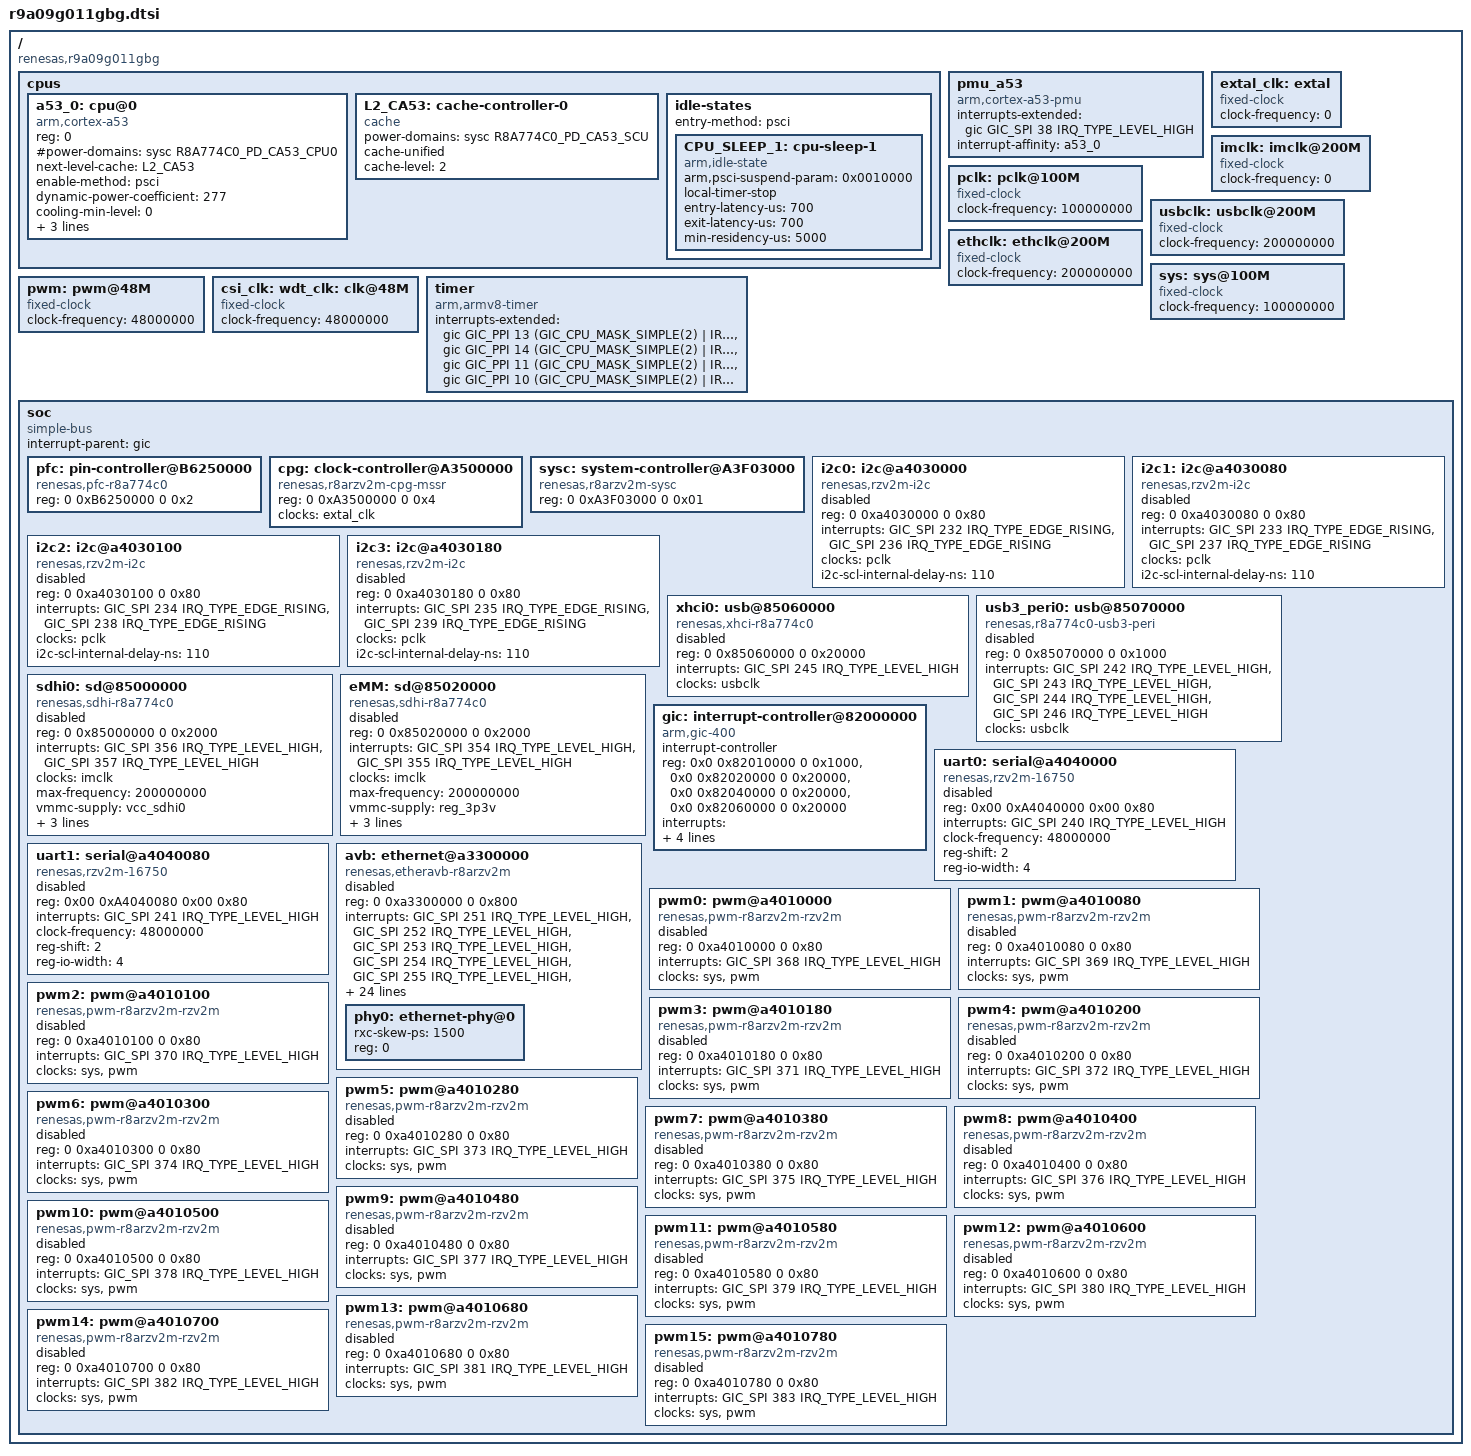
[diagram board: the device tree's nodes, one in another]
// SPDX-License-Identifier: GPL-2.0
/*
 * Device Tree Source for the RZ/V2M (R9A09G011GBG) SoC
 *
 * Copyright (C) 2019 Renesas Electronics Corp.
 */

#include <dt-bindings/clock/r9a09g011gbg-cpg-mssr.h>
#include <dt-bindings/interrupt-controller/arm-gic.h>
#include <dt-bindings/power/r9a09g011gbg-sysc.h>

/ {
    compatible = "renesas,r9a09g011gbg";
    #address-cells = <2>;
    #size-cells = <2>;


    cpus {
        #address-cells = <1>;
        #size-cells = <0>;

        a53_0: cpu@0 {
            compatible = "arm,cortex-a53", "arm,armv8";
            reg = <0>;
            device_type = "cpu";
            #power-domains = <&sysc R8A774C0_PD_CA53_CPU0>;
            next-level-cache = <&L2_CA53>;
            enable-method = "psci";
            #cooling-cells = <2>;
            dynamic-power-coefficient = <277>;
            cooling-min-level = <0>;
            cooling-max-level = <2>;
            cpu-idle-states = <&CPU_SLEEP_1>;
            clocks = <&cpg CPG_CORE R8A774C0_CLK_Z2>;
        };

        L2_CA53: cache-controller-0 {
            compatible = "cache";
            power-domains = <&sysc R8A774C0_PD_CA53_SCU>;
            cache-unified;
            cache-level = <2>;
        };

        idle-states {
            entry-method = "psci";

            CPU_SLEEP_1: cpu-sleep-1 {
                compatible = "arm,idle-state";
                arm,psci-suspend-param = <0x0010000>;
                local-timer-stop;
                entry-latency-us = <700>;
                exit-latency-us = <700>;
                min-residency-us = <5000>;
                status = "okay";
            };
        };
    };

    pmu_a53 { /* Support only for core0 not core1 */
        compatible = "arm,cortex-a53-pmu";
        interrupts-extended = <&gic GIC_SPI 38 IRQ_TYPE_LEVEL_HIGH>;
        interrupt-affinity = <&a53_0>;
    };

    /* used cpg(clock pulse generator) */
    extal_clk: extal {
        compatible = "fixed-clock";
        #clock-cells = <0>;
        /* This value must be overridden by the board */
        clock-frequency = <0>;
    };
    imclk: imclk@200M {
        #clock-cells = <0>;
        compatible = "fixed-clock";
        clock-frequency = <0>;
    };
    pclk: pclk@100M {
        #clock-cells = <0>;
        compatible = "fixed-clock";
        clock-frequency = <100000000>;
    };

    usbclk: usbclk@200M {
        #clock-cells = <0>;
        compatible = "fixed-clock";
        clock-frequency = <200000000>;
    };
    ethclk: ethclk@200M {
        #clock-cells = <0>;
        compatible = "fixed-clock";
        clock-frequency = <200000000>;
    };
    sys: sys@100M {
        #clock-cells = <0>;
        compatible = "fixed-clock";
        clock-frequency = <100000000>;
    };
    pwm: pwm@48M {
        #clock-cells = <0>;
        compatible = "fixed-clock";
        clock-frequency = <48000000>;
    };
    csi_clk: wdt_clk: pclk48: clk@48M {
        #clock-cells = <0>;
        compatible = "fixed-clock";
        clock-frequency = <48000000>;
    };

    timer {
        compatible = "arm,armv8-timer";
        interrupts-extended = <&gic GIC_PPI 13 (GIC_CPU_MASK_SIMPLE(2) | IRQ_TYPE_LEVEL_LOW)>,
                      <&gic GIC_PPI 14 (GIC_CPU_MASK_SIMPLE(2) | IRQ_TYPE_LEVEL_LOW)>,
                      <&gic GIC_PPI 11 (GIC_CPU_MASK_SIMPLE(2) | IRQ_TYPE_LEVEL_LOW)>,
                      <&gic GIC_PPI 10 (GIC_CPU_MASK_SIMPLE(2) | IRQ_TYPE_LEVEL_LOW)>;
    };

    soc: soc {
        compatible = "simple-bus";
        interrupt-parent = <&gic>;
        #address-cells = <2>;
        #size-cells = <2>;
        ranges;

        pfc: pin-controller@B6250000 {
            compatible = "renesas,pfc-r8a774c0";
            reg = <0 0xB6250000 0 0x2>;
        };

        cpg: clock-controller@A3500000 {
            compatible = "renesas,r8arzv2m-cpg-mssr";
            reg = <0 0xA3500000 0 0x4>;
            clocks = <&extal_clk>;
            clock-names = "extal";
            #clock-cells = <2>;
            #power-domain-cells = <0>;
            #reset-cells = <1>;
        };

        sysc: system-controller@A3F03000 {
            compatible = "renesas,r8arzv2m-sysc";
            reg = <0 0xA3F03000 0 0x01>;
            #power-domain-cells = <1>;
        };

        i2c0: i2c@a4030000 {
            #address-cells = <1>;
            #size-cells = <0>;
            compatible = "renesas,rzv2m-i2c";
            reg = <0 0xa4030000 0 0x80>;
            interrupts = <GIC_SPI 232 IRQ_TYPE_EDGE_RISING>,<GIC_SPI 236 IRQ_TYPE_EDGE_RISING>;
            clocks = <&pclk>;
            i2c-scl-internal-delay-ns = <110>;
            status = "disabled";
        };

        i2c1: i2c@a4030080 {
            #address-cells = <1>;
            #size-cells = <0>;
            compatible = "renesas,rzv2m-i2c";
            reg = <0 0xa4030080 0 0x80>;
            interrupts = <GIC_SPI 233 IRQ_TYPE_EDGE_RISING>,<GIC_SPI 237 IRQ_TYPE_EDGE_RISING>;
            clocks = <&pclk>;
            i2c-scl-internal-delay-ns = <110>;
            status = "disabled";
        };

        i2c2: i2c@a4030100 {
            #address-cells = <1>;
            #size-cells = <0>;
            compatible = "renesas,rzv2m-i2c";
            reg = <0 0xa4030100 0 0x80>;
            interrupts = <GIC_SPI 234 IRQ_TYPE_EDGE_RISING>,<GIC_SPI 238 IRQ_TYPE_EDGE_RISING>;
            clocks = <&pclk>;
            i2c-scl-internal-delay-ns = <110>;
            status = "disabled";
        };

        i2c3: i2c@a4030180 {
            #address-cells = <1>;
            #size-cells = <0>;
            compatible = "renesas,rzv2m-i2c";
            reg = <0 0xa4030180 0 0x80>;
            interrupts = <GIC_SPI 235 IRQ_TYPE_EDGE_RISING>,<GIC_SPI 239 IRQ_TYPE_EDGE_RISING>;
            clocks = <&pclk>;
            i2c-scl-internal-delay-ns = <110>;
            status = "disabled";
        };

        xhci0: usb@85060000 {
            compatible = "renesas,xhci-r8a774c0",
                     "renesas,rzv2m-xhci";
            reg = <0 0x85060000 0 0x20000>;
            interrupts = <GIC_SPI 245 IRQ_TYPE_LEVEL_HIGH>;
            clocks =  <&usbclk>;
            status = "disabled";
        };

        usb3_peri0: usb@85070000 {
            compatible = "renesas,r8a774c0-usb3-peri",
                     "renesas,rcar-gen3-usb3-peri";
            reg = <0 0x85070000 0 0x1000>;
            interrupts = <GIC_SPI 242 IRQ_TYPE_LEVEL_HIGH>,
                     <GIC_SPI 243 IRQ_TYPE_LEVEL_HIGH>,
                     <GIC_SPI 244 IRQ_TYPE_LEVEL_HIGH>,
                     <GIC_SPI 246 IRQ_TYPE_LEVEL_HIGH>;
            clocks =  <&usbclk>;
            status = "disabled";
        };

        sdhi0: sd@85000000 {    /* used sh card boot */
            compatible = "renesas,sdhi-r8a774c0",
                     "renesas,rcar-gen3-sdhi";
            reg = <0 0x85000000 0 0x2000>;
            interrupts = <GIC_SPI 356 IRQ_TYPE_LEVEL_HIGH>, <GIC_SPI 357 IRQ_TYPE_LEVEL_HIGH>;
            clocks = <&imclk>;
            max-frequency = <200000000>;
            vmmc-supply = <&vcc_sdhi0>;
            bus-width = <4>;
            sd-uhs-sdr50;
            sd-uhs-sdr104;
            status = "disable";
        };

        eMM: sd@85020000 {
            compatible = "renesas,sdhi-r8a774c0",
                    "renesas,rcar-gen3-sdhi";
            reg = <0 0x85020000 0 0x2000>;
            interrupts = <GIC_SPI 354 IRQ_TYPE_LEVEL_HIGH>, <GIC_SPI 355 IRQ_TYPE_LEVEL_HIGH>;
            clocks = <&imclk>;
            max-frequency = <200000000>;
            vmmc-supply = <&reg_3p3v>;
            vqmmc-supply = <&reg_1p8v>;
            bus-width = <8>;
            non-removable;
            status = "disable";
        };

        gic: interrupt-controller@82000000 {
            compatible = "arm,gic-400";
            #interrupt-cells = <3>;
            #address-cells = <0>;
            interrupt-controller;
            reg = <0x0 0x82010000 0 0x1000>,
                  <0x0 0x82020000 0 0x20000>,
                  <0x0 0x82040000 0 0x20000>,
                  <0x0 0x82060000 0 0x20000>;
            interrupts = <GIC_PPI 9
                    (GIC_CPU_MASK_SIMPLE(2) | IRQ_TYPE_LEVEL_HIGH)>;
            clocks = <&cpg CPG_MOD 408>;
            clock-names = "clk";
            power-domains = <&sysc R8A774C0_PD_ALWAYS_ON>;
            resets = <&cpg 408>;
        };

        uart0: serial@a4040000 {
            compatible = "renesas,rzv2m-16750", "ns16750";
            reg = <0x00 0xA4040000 0x00 0x80>;
            interrupts = <GIC_SPI 240 IRQ_TYPE_LEVEL_HIGH>;
            clock-frequency = <48000000>;
            reg-shift = <2>;
            reg-io-width = <4>;
            status = "disabled";
        };

        uart1: serial@a4040080 {
            compatible = "renesas,rzv2m-16750", "ns16750";
            reg = <0x00 0xA4040080 0x00 0x80>;
            interrupts = <GIC_SPI 241 IRQ_TYPE_LEVEL_HIGH>;
            clock-frequency = <48000000>;
            reg-shift = <2>;
            reg-io-width = <4>;
            status = "disabled";
        };

        avb: ethernet@a3300000 {
            compatible = "renesas,etheravb-r8arzv2m",
                     "renesas,etheravb-rcar-gen3";
            reg = <0 0xa3300000 0 0x800>;
            interrupts = <GIC_SPI 251 IRQ_TYPE_LEVEL_HIGH>,
                     <GIC_SPI 252 IRQ_TYPE_LEVEL_HIGH>,
                     <GIC_SPI 253 IRQ_TYPE_LEVEL_HIGH>,
                     <GIC_SPI 254 IRQ_TYPE_LEVEL_HIGH>,
                     <GIC_SPI 255 IRQ_TYPE_LEVEL_HIGH>,
                     <GIC_SPI 256 IRQ_TYPE_LEVEL_HIGH>,
                     <GIC_SPI 257 IRQ_TYPE_LEVEL_HIGH>,
                     <GIC_SPI 258 IRQ_TYPE_LEVEL_HIGH>,
                     <GIC_SPI 259 IRQ_TYPE_LEVEL_HIGH>,
                     <GIC_SPI 260 IRQ_TYPE_LEVEL_HIGH>,
                     <GIC_SPI 261 IRQ_TYPE_LEVEL_HIGH>,
                     <GIC_SPI 262 IRQ_TYPE_LEVEL_HIGH>,
                     <GIC_SPI 263 IRQ_TYPE_LEVEL_HIGH>,
                     <GIC_SPI 264 IRQ_TYPE_LEVEL_HIGH>,
                     <GIC_SPI 265 IRQ_TYPE_LEVEL_HIGH>,
                     <GIC_SPI 266 IRQ_TYPE_LEVEL_HIGH>,
                     <GIC_SPI 267 IRQ_TYPE_LEVEL_HIGH>,
                     <GIC_SPI 268 IRQ_TYPE_LEVEL_HIGH>,
                     <GIC_SPI 269 IRQ_TYPE_LEVEL_HIGH>,
                     <GIC_SPI 270 IRQ_TYPE_LEVEL_HIGH>,
                     <GIC_SPI 271 IRQ_TYPE_LEVEL_HIGH>,
                     <GIC_SPI 272 IRQ_TYPE_LEVEL_HIGH>,
                     <GIC_SPI 273 IRQ_TYPE_LEVEL_HIGH
                     GIC_SPI 275 IRQ_TYPE_LEVEL_HIGH
                     GIC_SPI 277 IRQ_TYPE_LEVEL_HIGH>,
                     <GIC_SPI 274 IRQ_TYPE_LEVEL_HIGH
                     GIC_SPI 276 IRQ_TYPE_LEVEL_HIGH
                     GIC_SPI 278 IRQ_TYPE_LEVEL_HIGH>,
                     <GIC_SPI 279 IRQ_TYPE_LEVEL_HIGH>;
            interrupt-names = "ch0", "ch1", "ch2", "ch3",
                      "ch4", "ch5", "ch6", "ch7",
                      "ch8", "ch9", "ch10", "ch11",
                      "ch12", "ch13", "ch14", "ch15",
                      "ch16", "ch17", "ch18", "ch19",
                      "ch20", "ch21", "ch22", "ch23",
                      "ch24";
            clocks = <&ethclk>;
            renesas,no-ether-link;
            phy-handle = <&phy0>;
            phy-mode = "rgmii";
            #address-cells = <1>;
            #size-cells = <0>;
            status = "disable";

            phy0: ethernet-phy@0 {
                rxc-skew-ps = <1500>;
                reg = <0>;
            };
        };

        pwm0: pwm@a4010000 {
            compatible = "renesas,pwm-r8arzv2m-rzv2m", "renesas,pwm-v2m";
            reg = <0 0xa4010000 0 0x80>;
            interrupts = <GIC_SPI 368 IRQ_TYPE_LEVEL_HIGH>;
            clocks = <&sys>, <&pwm>;
            clock-names = "sys", "pwm";
            #pwm-cells = <2>;
            status = "disabled";
        };

        pwm1: pwm@a4010080 {
            compatible = "renesas,pwm-r8arzv2m-rzv2m", "renesas,pwm-v2m";
            reg = <0 0xa4010080 0 0x80>;
            interrupts = <GIC_SPI 369 IRQ_TYPE_LEVEL_HIGH>;
            clocks = <&sys>, <&pwm>;
            clock-names = "sys", "pwm";
            #pwm-cells = <2>;
            status = "disabled";
        };

        pwm2: pwm@a4010100 {
            compatible = "renesas,pwm-r8arzv2m-rzv2m", "renesas,pwm-v2m";
            reg = <0 0xa4010100 0 0x80>;
            interrupts = <GIC_SPI 370 IRQ_TYPE_LEVEL_HIGH>;
            clocks = <&sys>, <&pwm>;
            clock-names = "sys", "pwm";
            #pwm-cells = <2>;
            status = "disabled";
        };

        pwm3: pwm@a4010180 {
            compatible = "renesas,pwm-r8arzv2m-rzv2m", "renesas,pwm-v2m";
            reg = <0 0xa4010180 0 0x80>;
            interrupts = <GIC_SPI 371 IRQ_TYPE_LEVEL_HIGH>;
            clocks = <&sys>, <&pwm>;
            clock-names = "sys", "pwm";
            #pwm-cells = <2>;
            status = "disabled";
        };

        pwm4: pwm@a4010200 {
            compatible = "renesas,pwm-r8arzv2m-rzv2m", "renesas,pwm-v2m";
            reg = <0 0xa4010200 0 0x80>;
            interrupts = <GIC_SPI 372 IRQ_TYPE_LEVEL_HIGH>;
            clocks = <&sys>, <&pwm>;
            clock-names = "sys", "pwm";
            #pwm-cells = <2>;
            status = "disabled";
        };

        pwm5: pwm@a4010280 {
            compatible = "renesas,pwm-r8arzv2m-rzv2m", "renesas,pwm-v2m";
            reg = <0 0xa4010280 0 0x80>;
            interrupts = <GIC_SPI 373 IRQ_TYPE_LEVEL_HIGH>;
            clocks = <&sys>, <&pwm>;
            clock-names = "sys", "pwm";
            #pwm-cells = <2>;
            status = "disabled";
        };

        pwm6: pwm@a4010300 {
            compatible = "renesas,pwm-r8arzv2m-rzv2m", "renesas,pwm-v2m";
            reg = <0 0xa4010300 0 0x80>;
            interrupts = <GIC_SPI 374 IRQ_TYPE_LEVEL_HIGH>;
            clocks = <&sys>, <&pwm>;
            clock-names = "sys", "pwm";
            #pwm-cells = <2>;
            status = "disabled";
        };

        pwm7: pwm@a4010380 {
            compatible = "renesas,pwm-r8arzv2m-rzv2m", "renesas,pwm-v2m";
            reg = <0 0xa4010380 0 0x80>;
            interrupts = <GIC_SPI 375 IRQ_TYPE_LEVEL_HIGH>;
            clocks = <&sys>, <&pwm>;
            clock-names = "sys", "pwm";
            #pwm-cells = <2>;
            status = "disabled";
        };

        pwm8: pwm@a4010400 {
            compatible = "renesas,pwm-r8arzv2m-rzv2m", "renesas,pwm-v2m";
            reg = <0 0xa4010400 0 0x80>;
            interrupts = <GIC_SPI 376 IRQ_TYPE_LEVEL_HIGH>;
            clocks = <&sys>, <&pwm>;
            clock-names = "sys", "pwm";
            #pwm-cells = <2>;
            status = "disabled";
        };

        pwm9: pwm@a4010480 {
            compatible = "renesas,pwm-r8arzv2m-rzv2m", "renesas,pwm-v2m";
            reg = <0 0xa4010480 0 0x80>;
            interrupts = <GIC_SPI 377 IRQ_TYPE_LEVEL_HIGH>;
            clocks = <&sys>, <&pwm>;
            clock-names = "sys", "pwm";
            #pwm-cells = <2>;
            status = "disabled";
        };

        pwm10: pwm@a4010500 {
            compatible = "renesas,pwm-r8arzv2m-rzv2m", "renesas,pwm-v2m";
            reg = <0 0xa4010500 0 0x80>;
            interrupts = <GIC_SPI 378 IRQ_TYPE_LEVEL_HIGH>;
            clocks = <&sys>, <&pwm>;
            clock-names = "sys", "pwm";
            #pwm-cells = <2>;
            status = "disabled";
        };

        pwm11: pwm@a4010580 {
            compatible = "renesas,pwm-r8arzv2m-rzv2m", "renesas,pwm-v2m";
            reg = <0 0xa4010580 0 0x80>;
            interrupts = <GIC_SPI 379 IRQ_TYPE_LEVEL_HIGH>;
            clocks = <&sys>, <&pwm>;
            clock-names = "sys", "pwm";
            #pwm-cells = <2>;
            status = "disabled";
        };

        pwm12: pwm@a4010600 {
            compatible = "renesas,pwm-r8arzv2m-rzv2m", "renesas,pwm-v2m";
            reg = <0 0xa4010600 0 0x80>;
            interrupts = <GIC_SPI 380 IRQ_TYPE_LEVEL_HIGH>;
            clocks = <&sys>, <&pwm>;
            clock-names = "sys", "pwm";
            #pwm-cells = <2>;
            status = "disabled";
        };

        pwm13: pwm@a4010680 {
            compatible = "renesas,pwm-r8arzv2m-rzv2m", "renesas,pwm-v2m";
            reg = <0 0xa4010680 0 0x80>;
            interrupts = <GIC_SPI 381 IRQ_TYPE_LEVEL_HIGH>;
            clocks = <&sys>, <&pwm>;
            clock-names = "sys", "pwm";
            #pwm-cells = <2>;
            status = "disabled";
        };

        pwm14: pwm@a4010700 {
            compatible = "renesas,pwm-r8arzv2m-rzv2m", "renesas,pwm-v2m";
            reg = <0 0xa4010700 0 0x80>;
            interrupts = <GIC_SPI 382 IRQ_TYPE_LEVEL_HIGH>;
            clocks = <&sys>, <&pwm>;
            clock-names = "sys", "pwm";
            #pwm-cells = <2>;
            status = "disabled";
        };

        pwm15: pwm@a4010780 {
            compatible = "renesas,pwm-r8arzv2m-rzv2m", "renesas,pwm-v2m";
            reg = <0 0xa4010780 0 0x80>;
            interrupts = <GIC_SPI 383 IRQ_TYPE_LEVEL_HIGH>;
            clocks = <&sys>, <&pwm>;
            clock-names = "sys", "pwm";
            #pwm-cells = <2>;
            status = "disabled";
        };
    };
};
